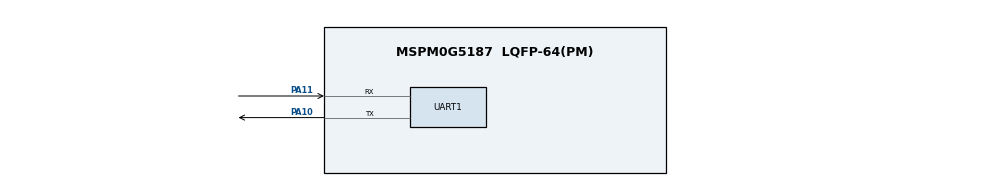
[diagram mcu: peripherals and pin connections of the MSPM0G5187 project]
//@cliArgs --device "MSPM0G518X" --package "LQFP-64(PM)" --part "Default"
//@v2CliArgs --device "MSPM0G5187" --package "LQFP-64(PM)"
// @cliArgs --board /ti/boards/LP_MSPM0G5187 --rtos nortos

/**
 * Import the modules used in this configuration.
 */
const SYSCTL        = scripting.addModule("/ti/driverlib/SYSCTL");
const UART          = scripting.addModule("/ti/driverlib/UART", {}, false);
const UART1         = UART.addInstance();
const ProjectConfig = scripting.addModule("/ti/project_config/ProjectConfig");

/**
 * Write custom configuration values to the imported modules.
 */
const divider9       = system.clockTree["UDIV"];
divider9.divideValue = 2;

const multiplier2         = system.clockTree["PLL_QDIV"];
multiplier2.multiplyValue = 5;

const mux8       = system.clockTree["HSCLKMUX"];
mux8.inputSelect = "HSCLKMUX_SYSPLL0";

SYSCTL.forceDefaultClkConfig = true;
SYSCTL.clockTreeEn           = true;

const Board = scripting.addModule("/ti/driverlib/Board", {}, false);

UART1.$name                    = "UART_0";
UART1.targetBaudRate           = 115200;
UART1.enabledInterrupts        = ["RX"];
UART1.peripheral.rxPin.$assign = "PA11";
UART1.peripheral.txPin.$assign = "PA10";

ProjectConfig.genLibNPU = true;
